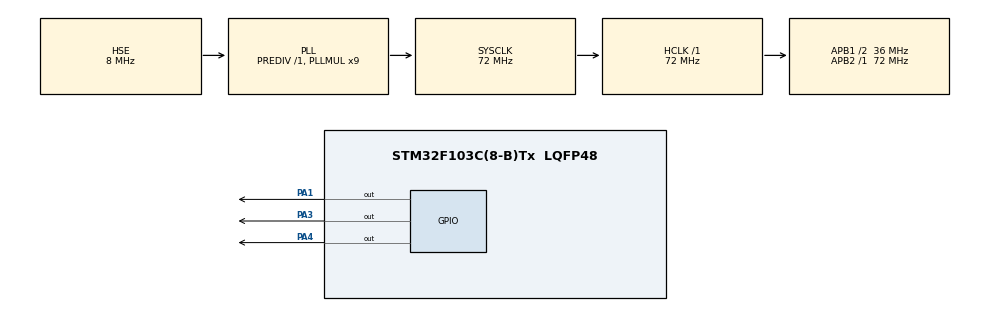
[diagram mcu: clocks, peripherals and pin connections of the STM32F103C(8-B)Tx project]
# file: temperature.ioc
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Mcu.Family=STM32F1
Mcu.Name=STM32F103C(8-B)Tx
Mcu.Package=LQFP48
NVIC.PriorityGroup=NVIC_PRIORITYGROUP_4
NVIC.RCC_IRQn=true\:0\:0\:false\:false\:true\:true\:false\:true
PA1.Signal=GPIO_Output
PA3.Signal=GPIO_Output
PA4.Signal=GPIO_Output
PD0-OSC_IN.Mode=HSE-External-Clock-Source
PD0-OSC_IN.Signal=RCC_OSC_IN
PD1-OSC_OUT.Mode=HSE-External-Clock-Source
PD1-OSC_OUT.Signal=RCC_OSC_OUT
ProjectManager.HeapSize=0x200
ProjectManager.StackSize=0x400
ProjectManager.TargetToolchain=STM32CubeIDE
RCC.AHBFreq_Value=72000000
RCC.APB1CLKDivider=RCC_HCLK_DIV2
RCC.APB1Freq_Value=36000000
RCC.APB1TimFreq_Value=72000000
RCC.APB2Freq_Value=72000000
RCC.APB2TimFreq_Value=72000000
RCC.HCLKFreq_Value=72000000
RCC.PLLMUL=RCC_PLL_MUL9
RCC.PLLSourceVirtual=RCC_PLLSOURCE_HSE
RCC.SYSCLKFreq_VALUE=72000000
RCC.SYSCLKSource=RCC_SYSCLKSOURCE_PLLCLK
RCC.USBFreq_Value=72000000
TIM1.Prescaler=72-1
VP_SYS_VS_ND.Mode=No_Debug
VP_TIM1_VS_ClockSourceINT.Mode=Internal
board=custom

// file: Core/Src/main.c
/* USER CODE BEGIN Header */
/**
  ******************************************************************************
  * @file           : main.c
  * @brief          : Main program body
  ******************************************************************************
  * @attention
  *
  * Copyright (c) 2024 STMicroelectronics.
  * All rights reserved.
  *
  * This software is licensed under terms that can be found in the LICENSE file
  * in the root directory of this software component.
  * If no LICENSE file comes with this software, it is provided AS-IS.
  *
  ******************************************************************************
  */
/* USER CODE END Header */
#include "main.h"
#define DHT11_PORT GPIOA
#define DHT11_PIN  GPIO_PIN_3
extern TIM_HandleTypeDef htim1;

/* USER CODE BEGIN PTD */
void Set_Pin_Output(GPIO_TypeDef *GPIOx, uint16_t GPIO_Pin) {
    GPIO_InitTypeDef GPIO_InitStruct = {0};
    GPIO_InitStruct.Pin = GPIO_Pin;
    GPIO_InitStruct.Mode = GPIO_MODE_OUTPUT_PP;
    GPIO_InitStruct.Speed = GPIO_SPEED_FREQ_LOW;
    HAL_GPIO_Init(GPIOx, &GPIO_InitStruct);
}

void Set_Pin_Input(GPIO_TypeDef *GPIOx, uint16_t GPIO_Pin) {
    GPIO_InitTypeDef GPIO_InitStruct = {0};
    GPIO_InitStruct.Pin = GPIO_Pin;
    GPIO_InitStruct.Mode = GPIO_MODE_INPUT;
    GPIO_InitStruct.Pull = GPIO_NOPULL;
    HAL_GPIO_Init(GPIOx, &GPIO_InitStruct);
}
/* USER CODE END PTD */
void delay (uint16_t us)
{
	__HAL_TIM_SET_COUNTER(&htim1,0);  // set the counter value a 0
	while (__HAL_TIM_GET_COUNTER(&htim1) < us);  // wait for the counter to reach the us input in the parameter
}
/* USER CODE BEGIN PD */
void DHT11_Start(void){
	Set_Pin_Output (DHT11_PORT, DHT11_PIN);
	HAL_GPIO_WritePin (DHT11_PORT, DHT11_PIN, 0);
	delay (18000);   // wait for 18ms
	Set_Pin_Input(DHT11_PORT, DHT11_PIN);
}
/* USER CODE END PD */

/* USER CODE BEGIN PM */
uint8_t Check_Response(void){
	uint8_t Response = 0;
	delay (40);
	if (!(HAL_GPIO_ReadPin (DHT11_PORT, DHT11_PIN)))
	{
		delay (80);
		if ((HAL_GPIO_ReadPin (DHT11_PORT, DHT11_PIN))) Response = 1;
		else Response = -1;
	}
	while ((HAL_GPIO_ReadPin (DHT11_PORT, DHT11_PIN)));

	return Response;
}
/* USER CODE END PM */
uint8_t DHT11_Read(void){
	uint8_t i,j;
	for(j=0;j<8;j++){
		while (!(HAL_GPIO_ReadPin(DHT11_PORT, DHT11_PIN)));
		delay (40);
		if (!(HAL_GPIO_ReadPin (DHT11_PORT, DHT11_PIN)))
		{
			i&= ~(1<<(7-j));
		}
		else i|= (1<<(7-j));
		while ((HAL_GPIO_ReadPin (DHT11_PORT, DHT11_PIN)));
	}
	return i;
}

TIM_HandleTypeDef htim1;

void SystemClock_Config(void);
static void MX_GPIO_Init(void);
static void MX_TIM1_Init(void);

int main(void)
{
	uint8_t Presence = 0;
	uint8_t Rh_byte1, Rh_byte2, Temp_byte1, Temp_byte2, SUM;
	int TEMP, RH;
	float Temperature, Humidity;
  /* USER CODE BEGIN 1 */
	HAL_TIM_Base_Start(&htim1);
  /* USER CODE END 1 */
  /* MCU Configuration--------------------------------------------------------*/
	HAL_Delay(2000);
  /* Reset of all peripherals, Initializes the Flash interface and the Systick. */
  HAL_Init();

  /* Configure the system clock */
  SystemClock_Config();

  /* Initialize all configured peripherals */
  MX_GPIO_Init();
  MX_TIM1_Init();

  /* Infinite loop */
  while (1)
  {
	  DHT11_Start();
	  Presence = Check_Response();
	  Rh_byte1 = DHT11_Read ();
      Rh_byte2 = DHT11_Read ();
      Temp_byte1 = DHT11_Read ();
      Temp_byte2 = DHT11_Read ();
      SUM = DHT11_Read();

      TEMP = Temp_byte1;
      RH = Rh_byte1;

      Temperature = (float) TEMP;
      Humidity = (float) RH;
      HAL_Delay(3000);
  }
}

void SystemClock_Config(void)
{
  RCC_OscInitTypeDef RCC_OscInitStruct = {0};
  RCC_ClkInitTypeDef RCC_ClkInitStruct = {0};

  /** Initializes the RCC Oscillators according to the specified parameters
  * in the RCC_OscInitTypeDef structure.
  */
  RCC_OscInitStruct.OscillatorType = RCC_OSCILLATORTYPE_HSE;
  RCC_OscInitStruct.HSEState = RCC_HSE_BYPASS;
  RCC_OscInitStruct.HSEPredivValue = RCC_HSE_PREDIV_DIV1;
  RCC_OscInitStruct.HSIState = RCC_HSI_ON;
  RCC_OscInitStruct.PLL.PLLState = RCC_PLL_ON;
  RCC_OscInitStruct.PLL.PLLSource = RCC_PLLSOURCE_HSE;
  RCC_OscInitStruct.PLL.PLLMUL = RCC_PLL_MUL9;
  if (HAL_RCC_OscConfig(&RCC_OscInitStruct) != HAL_OK)
  {
    Error_Handler();
  }

  /** Initializes the CPU, AHB and APB buses clocks
  */
  RCC_ClkInitStruct.ClockType = RCC_CLOCKTYPE_HCLK|RCC_CLOCKTYPE_SYSCLK
                              |RCC_CLOCKTYPE_PCLK1|RCC_CLOCKTYPE_PCLK2;
  RCC_ClkInitStruct.SYSCLKSource = RCC_SYSCLKSOURCE_PLLCLK;
  RCC_ClkInitStruct.AHBCLKDivider = RCC_SYSCLK_DIV1;
  RCC_ClkInitStruct.APB1CLKDivider = RCC_HCLK_DIV2;
  RCC_ClkInitStruct.APB2CLKDivider = RCC_HCLK_DIV1;

  if (HAL_RCC_ClockConfig(&RCC_ClkInitStruct, FLASH_LATENCY_2) != HAL_OK)
  {
    Error_Handler();
  }
}

static void MX_TIM1_Init(void)
{

  TIM_ClockConfigTypeDef sClockSourceConfig = {0};
  TIM_MasterConfigTypeDef sMasterConfig = {0};

  htim1.Instance = TIM1;
  htim1.Init.Prescaler = 72-1;
  htim1.Init.CounterMode = TIM_COUNTERMODE_UP;
  htim1.Init.Period = 65535;
  htim1.Init.ClockDivision = TIM_CLOCKDIVISION_DIV1;
  htim1.Init.RepetitionCounter = 0;
  htim1.Init.AutoReloadPreload = TIM_AUTORELOAD_PRELOAD_DISABLE;
  if (HAL_TIM_Base_Init(&htim1) != HAL_OK)
  {
    Error_Handler();
  }
  sClockSourceConfig.ClockSource = TIM_CLOCKSOURCE_INTERNAL;
  if (HAL_TIM_ConfigClockSource(&htim1, &sClockSourceConfig) != HAL_OK)
  {
    Error_Handler();
  }
  sMasterConfig.MasterOutputTrigger = TIM_TRGO_RESET;
  sMasterConfig.MasterSlaveMode = TIM_MASTERSLAVEMODE_DISABLE;
  if (HAL_TIMEx_MasterConfigSynchronization(&htim1, &sMasterConfig) != HAL_OK)
  {
    Error_Handler();
  }

}

static void MX_GPIO_Init(void)
{
  GPIO_InitTypeDef GPIO_InitStruct = {0};

  /* GPIO Ports Clock Enable */
  __HAL_RCC_GPIOD_CLK_ENABLE();
  __HAL_RCC_GPIOA_CLK_ENABLE();

  /*Configure GPIO pin Output Level */
  HAL_GPIO_WritePin(GPIOA, GPIO_PIN_1|GPIO_PIN_3|GPIO_PIN_4, GPIO_PIN_RESET);

  /*Configure GPIO pins : PA1 PA3 PA4 */
  GPIO_InitStruct.Pin = GPIO_PIN_1|GPIO_PIN_3|GPIO_PIN_4;
  GPIO_InitStruct.Mode = GPIO_MODE_OUTPUT_PP;
  GPIO_InitStruct.Pull = GPIO_NOPULL;
  GPIO_InitStruct.Speed = GPIO_SPEED_FREQ_LOW;
  HAL_GPIO_Init(GPIOA, &GPIO_InitStruct);

}

void Error_Handler(void)
{
  __disable_irq();
  while (1)
  {
  }
}
